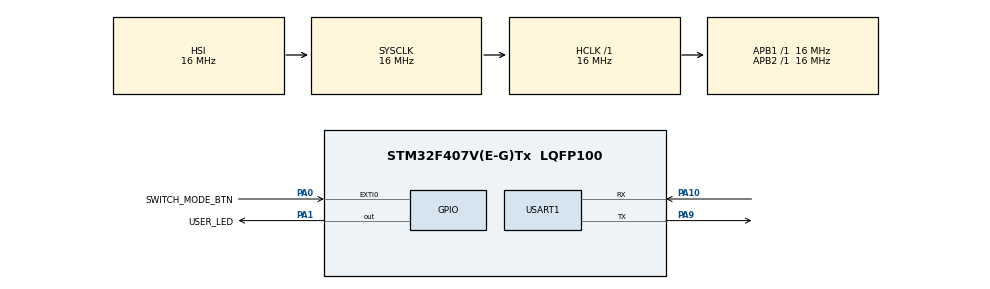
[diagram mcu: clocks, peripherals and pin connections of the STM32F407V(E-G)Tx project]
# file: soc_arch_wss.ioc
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Mcu.Family=STM32F4
Mcu.Name=STM32F407V(E-G)Tx
Mcu.Package=LQFP100
NVIC.EXTI0_IRQn=true\:0\:0\:false\:false\:true\:true\:true
NVIC.PriorityGroup=NVIC_PRIORITYGROUP_4
NVIC.RTC_Alarm_IRQn=true\:0\:0\:false\:false\:true\:true\:true
NVIC.TIM2_IRQn=true\:0\:0\:false\:false\:true\:true\:true
PA0-WKUP.GPIO_Label=SWITCH_MODE_BTN
PA0-WKUP.GPIO_ModeDefaultEXTI=GPIO_MODE_IT_RISING
PA0-WKUP.GPIO_PuPd=GPIO_PULLDOWN
PA0-WKUP.Signal=GPXTI0
PA1.GPIO_Label=USER_LED
PA1.Signal=GPIO_Output
PA10.Mode=Asynchronous
PA10.Signal=USART1_RX
PA9.Mode=Asynchronous
PA9.Signal=USART1_TX
PC14-OSC32_IN.Mode=LSE-External-Oscillator
PC14-OSC32_IN.Signal=RCC_OSC32_IN
PC15-OSC32_OUT.Mode=LSE-External-Oscillator
PC15-OSC32_OUT.Signal=RCC_OSC32_OUT
PH0-OSC_IN.Mode=HSE-External-Oscillator
PH0-OSC_IN.Signal=RCC_OSC_IN
PH1-OSC_OUT.Mode=HSE-External-Oscillator
PH1-OSC_OUT.Signal=RCC_OSC_OUT
ProjectManager.HeapSize=0x200
ProjectManager.StackSize=0x400
ProjectManager.TargetToolchain=STM32CubeIDE
RCC.AHBFreq_Value=16000000
RCC.APB1Freq_Value=16000000
RCC.APB2Freq_Value=16000000
RCC.CortexFreq_Value=16000000
RCC.HSE_VALUE=25000000
RCC.HSI_VALUE=16000000
RCC.RCC_RTC_Clock_Source=RCC_RTCCLKSOURCE_LSE
RCC.RCC_RTC_Clock_SourceVirtual=RCC_RTCCLKSOURCE_LSE
RCC.SYSCLKFreq_VALUE=16000000
RCC.VCOOutputFreq_Value=192000000
RTC.Alarm=RTC_ALARM_A
RTC.AlarmDateWeekDaySel=RTC_ALARMDATEWEEKDAYSEL_WEEKDAY
RTC.AlarmDateWeekDaySel_B=RTC_ALARMDATEWEEKDAYSEL_WEEKDAY
RTC.AlarmMaskDateWeekDay=RTC_ALARMMASK_DATEWEEKDAY
RTC.AlarmMaskDateWeekDay_B=RTC_ALARMMASK_DATEWEEKDAY
RTC.Alarm_B=RTC_ALARM_B
RTC.AsynchPrediv=127
RTC.Date=25
RTC.Format=RTC_FORMAT_BCD
RTC.Hours=15
RTC.Hours_A=8
RTC.Hours_B=22
RTC.Minutes=0
RTC.Minutes_A=0
RTC.Minutes_B=0
RTC.Month=RTC_MONTH_FEBRUARY
RTC.Seconds=0
RTC.SynchPrediv=255
RTC.Year=21
TIM2.AutoReloadPreload=TIM_AUTORELOAD_PRELOAD_ENABLE
TIM2.Period=100
TIM2.Prescaler=16000
USART1.VirtualMode=VM_ASYNC
VP_RTC_VS_RTC_Activate.Mode=RTC_Enabled
VP_RTC_VS_RTC_Alarm_A_Intern.Mode=Alarm A
VP_RTC_VS_RTC_Alarm_B_Intern.Mode=Alarm B
VP_RTC_VS_RTC_Calendar.Mode=RTC_Calendar
VP_TIM2_VS_ClockSourceINT.Mode=Internal
board=custom

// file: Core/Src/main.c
/* USER CODE BEGIN Header */
/**
 ******************************************************************************
 * @file           : main.c
 * @brief          : Main program body
 ******************************************************************************
 * @attention
 *
 * <h2><center>&copy; Copyright (c) 2021 STMicroelectronics.
 * All rights reserved.</center></h2>
 *
 * This software component is licensed by ST under BSD 3-Clause license,
 * the "License"; You may not use this file except in compliance with the
 * License. You may obtain a copy of the License at:
 *                        opensource.org/licenses/BSD-3-Clause
 *
 ******************************************************************************
 */
/* USER CODE END Header */
#include "main.h"

/* USER CODE BEGIN Includes */
#include <stdio.h>
#include "controller.h"
#include "button.h"
#include "rtc.h"
/* USER CODE END Includes */

/* USER CODE BEGIN PD */
#ifdef RENODE_ENV
#define DELAY_TIME 70000
#else
#define DELAY_TIME 30000
#endif
/* USER CODE END PD */

RTC_HandleTypeDef hrtc;

#ifndef RENODE_ENV
TIM_HandleTypeDef htim2;
#endif

UART_HandleTypeDef huart1;

#ifndef RENODE_ENV
void SystemClock_Config(void);
#endif
static void MX_GPIO_Init(void);
static void MX_USART1_UART_Init(void);
#ifndef RENODE_ENV
static void MX_TIM2_Init(void);
#endif
static void MX_RTC_Init(void);

int main(void) {

	/* MCU Configuration--------------------------------------------------------*/

	/* Reset of all peripherals, Initializes the Flash interface and the Systick. */
	HAL_Init();

	/* Configure the system clock */
#ifndef RENODE_ENV
	SystemClock_Config();
#endif

	/* Initialize all configured peripherals */
	MX_GPIO_Init();
	MX_USART1_UART_Init();
#ifndef RENODE_ENV
	MX_TIM2_Init();
#endif
	MX_RTC_Init();
	/* USER CODE BEGIN 2 */
	Controller_Init();
	/* USER CODE END 2 */

	/* Infinite loop */
	/* USER CODE BEGIN WHILE */
	while (1) {
		Controller_Handle();
		HAL_Delay(DELAY_TIME);
		/* USER CODE END WHILE */

	}
}

#ifndef RENODE_ENV
void SystemClock_Config(void) {
	RCC_OscInitTypeDef RCC_OscInitStruct = { 0 };
	RCC_ClkInitTypeDef RCC_ClkInitStruct = { 0 };
	RCC_PeriphCLKInitTypeDef PeriphClkInitStruct = { 0 };

	/** Configure the main internal regulator output voltage
	 */
	__HAL_RCC_PWR_CLK_ENABLE();
	__HAL_PWR_VOLTAGESCALING_CONFIG(PWR_REGULATOR_VOLTAGE_SCALE1);
	/** Initializes the RCC Oscillators according to the specified parameters
	 * in the RCC_OscInitTypeDef structure.
	 */
	RCC_OscInitStruct.OscillatorType = RCC_OSCILLATORTYPE_HSI
			| RCC_OSCILLATORTYPE_LSE;
	RCC_OscInitStruct.LSEState = RCC_LSE_ON;
	RCC_OscInitStruct.HSIState = RCC_HSI_ON;
	RCC_OscInitStruct.HSICalibrationValue = RCC_HSICALIBRATION_DEFAULT;
	RCC_OscInitStruct.PLL.PLLState = RCC_PLL_NONE;
	if (HAL_RCC_OscConfig(&RCC_OscInitStruct) != HAL_OK) {
		Error_Handler();
	}
	/** Initializes the CPU, AHB and APB buses clocks
	 */
	RCC_ClkInitStruct.ClockType = RCC_CLOCKTYPE_HCLK | RCC_CLOCKTYPE_SYSCLK
			| RCC_CLOCKTYPE_PCLK1 | RCC_CLOCKTYPE_PCLK2;
	RCC_ClkInitStruct.SYSCLKSource = RCC_SYSCLKSOURCE_HSI;
	RCC_ClkInitStruct.AHBCLKDivider = RCC_SYSCLK_DIV1;
	RCC_ClkInitStruct.APB1CLKDivider = RCC_HCLK_DIV1;
	RCC_ClkInitStruct.APB2CLKDivider = RCC_HCLK_DIV1;

	if (HAL_RCC_ClockConfig(&RCC_ClkInitStruct, FLASH_LATENCY_0) != HAL_OK) {
		Error_Handler();
	}
	PeriphClkInitStruct.PeriphClockSelection = RCC_PERIPHCLK_RTC;
	PeriphClkInitStruct.RTCClockSelection = RCC_RTCCLKSOURCE_LSE;
	if (HAL_RCCEx_PeriphCLKConfig(&PeriphClkInitStruct) != HAL_OK) {
		Error_Handler();
	}
}
#endif

static void MX_RTC_Init(void) {

	RTC_TimeTypeDef sTime = { 0 };
	RTC_DateTypeDef sDate = { 0 };
	RTC_AlarmTypeDef sAlarm = { 0 };

	/** Initialize RTC Only
	 */
	hrtc.Instance = RTC;
	hrtc.Init.HourFormat = RTC_HOURFORMAT_24;
	hrtc.Init.AsynchPrediv = 127;
	hrtc.Init.SynchPrediv = 255;
	hrtc.Init.OutPut = RTC_OUTPUT_DISABLE;
	hrtc.Init.OutPutPolarity = RTC_OUTPUT_POLARITY_HIGH;
	hrtc.Init.OutPutType = RTC_OUTPUT_TYPE_OPENDRAIN;
	if (HAL_RTC_Init(&hrtc) != HAL_OK) {
		Error_Handler();
	}

	/** Initialize RTC and set the Time and Date
	 */
	sTime.Hours = 0x15;
	sTime.Minutes = 0x0;
	sTime.Seconds = 0x0;
	sTime.DayLightSaving = RTC_DAYLIGHTSAVING_NONE;
	sTime.StoreOperation = RTC_STOREOPERATION_RESET;
	if (HAL_RTC_SetTime(&hrtc, &sTime, RTC_FORMAT_BCD) != HAL_OK) {
		Error_Handler();
	}
	sDate.WeekDay = RTC_WEEKDAY_MONDAY;
	sDate.Month = RTC_MONTH_FEBRUARY;
	sDate.Date = 0x25;
	sDate.Year = 0x21;

	if (HAL_RTC_SetDate(&hrtc, &sDate, RTC_FORMAT_BCD) != HAL_OK) {
		Error_Handler();
	}
	/** Enable the Alarm A
	 */
	sAlarm.AlarmTime.Hours = 0x8;
	sAlarm.AlarmTime.Minutes = 0x0;
	sAlarm.AlarmTime.Seconds = 0x0;
	sAlarm.AlarmTime.SubSeconds = 0x0;
	sAlarm.AlarmTime.DayLightSaving = RTC_DAYLIGHTSAVING_NONE;
	sAlarm.AlarmTime.StoreOperation = RTC_STOREOPERATION_RESET;
	sAlarm.AlarmMask = RTC_ALARMMASK_DATEWEEKDAY;
	sAlarm.AlarmSubSecondMask = RTC_ALARMSUBSECONDMASK_ALL;
	sAlarm.AlarmDateWeekDaySel = RTC_ALARMDATEWEEKDAYSEL_WEEKDAY;
	sAlarm.AlarmDateWeekDay = RTC_WEEKDAY_MONDAY;
	sAlarm.Alarm = RTC_ALARM_A;
	if (HAL_RTC_SetAlarm_IT(&hrtc, &sAlarm, RTC_FORMAT_BCD) != HAL_OK) {
		Error_Handler();
	}
	/** Enable the Alarm B
	 */
	sAlarm.AlarmTime.Hours = 0x22;
	sAlarm.AlarmDateWeekDay = RTC_WEEKDAY_MONDAY;
	sAlarm.Alarm = RTC_ALARM_B;
	if (HAL_RTC_SetAlarm_IT(&hrtc, &sAlarm, RTC_FORMAT_BCD) != HAL_OK) {
		Error_Handler();
	}

}

#ifndef RENODE_ENV
static void MX_TIM2_Init(void) {

	TIM_ClockConfigTypeDef sClockSourceConfig = { 0 };
	TIM_MasterConfigTypeDef sMasterConfig = { 0 };

	htim2.Instance = TIM2;
	htim2.Init.Prescaler = 16000;
	htim2.Init.CounterMode = TIM_COUNTERMODE_UP;
	htim2.Init.Period = 100;
	htim2.Init.ClockDivision = TIM_CLOCKDIVISION_DIV1;
	htim2.Init.AutoReloadPreload = TIM_AUTORELOAD_PRELOAD_ENABLE;
	if (HAL_TIM_Base_Init(&htim2) != HAL_OK) {
		Error_Handler();
	}
	sClockSourceConfig.ClockSource = TIM_CLOCKSOURCE_INTERNAL;
	if (HAL_TIM_ConfigClockSource(&htim2, &sClockSourceConfig) != HAL_OK) {
		Error_Handler();
	}
	sMasterConfig.MasterOutputTrigger = TIM_TRGO_RESET;
	sMasterConfig.MasterSlaveMode = TIM_MASTERSLAVEMODE_DISABLE;
	if (HAL_TIMEx_MasterConfigSynchronization(&htim2, &sMasterConfig)
			!= HAL_OK) {
		Error_Handler();
	}

}
#endif

static void MX_USART1_UART_Init(void) {

	huart1.Instance = USART1;
	huart1.Init.BaudRate = 115200;
	huart1.Init.WordLength = UART_WORDLENGTH_8B;
	huart1.Init.StopBits = UART_STOPBITS_1;
	huart1.Init.Parity = UART_PARITY_NONE;
	huart1.Init.Mode = UART_MODE_TX_RX;
	huart1.Init.HwFlowCtl = UART_HWCONTROL_NONE;
	huart1.Init.OverSampling = UART_OVERSAMPLING_16;
	if (HAL_UART_Init(&huart1) != HAL_OK) {
		Error_Handler();
	}

}

static void MX_GPIO_Init(void) {
	GPIO_InitTypeDef GPIO_InitStruct = { 0 };

	/* GPIO Ports Clock Enable */
	__HAL_RCC_GPIOC_CLK_ENABLE();
	__HAL_RCC_GPIOH_CLK_ENABLE();
	__HAL_RCC_GPIOA_CLK_ENABLE();

	/*Configure GPIO pin Output Level */
	HAL_GPIO_WritePin(USER_LED_GPIO_Port, USER_LED_Pin, GPIO_PIN_RESET);

	/*Configure GPIO pin : SWITCH_MODE_BTN_Pin */
	GPIO_InitStruct.Pin = SWITCH_MODE_BTN_Pin;
	GPIO_InitStruct.Mode = GPIO_MODE_IT_RISING;
	GPIO_InitStruct.Pull = GPIO_PULLDOWN;
	HAL_GPIO_Init(SWITCH_MODE_BTN_GPIO_Port, &GPIO_InitStruct);

	/*Configure GPIO pin : USER_LED_Pin */
	GPIO_InitStruct.Pin = USER_LED_Pin;
	GPIO_InitStruct.Mode = GPIO_MODE_OUTPUT_PP;
	GPIO_InitStruct.Pull = GPIO_NOPULL;
	GPIO_InitStruct.Speed = GPIO_SPEED_FREQ_LOW;
	HAL_GPIO_Init(USER_LED_GPIO_Port, &GPIO_InitStruct);

	/* EXTI interrupt init*/
	HAL_NVIC_SetPriority(EXTI0_IRQn, 0, 0);
	HAL_NVIC_EnableIRQ(EXTI0_IRQn);

}

void Error_Handler(void) {
	__disable_irq();
	while (1) {
	}
}

/************************ (C) COPYRIGHT STMicroelectronics *****END OF FILE****/
